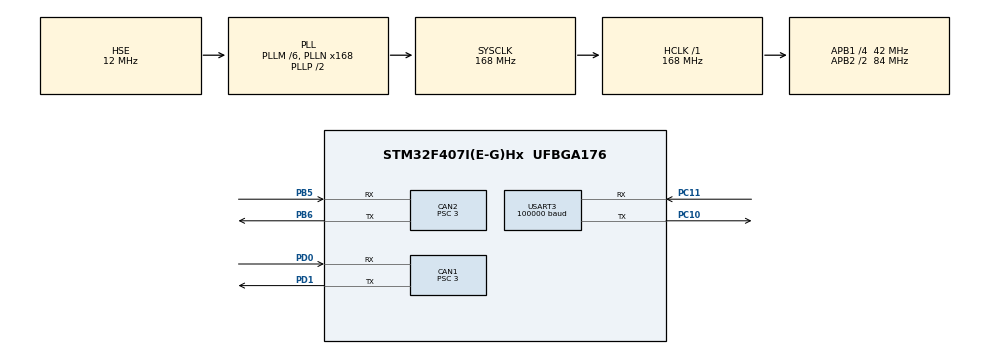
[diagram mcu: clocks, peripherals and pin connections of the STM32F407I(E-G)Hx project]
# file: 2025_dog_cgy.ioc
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CAN1.BS1=CAN_BS1_7TQ
CAN1.BS2=CAN_BS2_6TQ
CAN1.CalculateBaudRate=1000000
CAN1.CalculateTimeBit=1000
CAN1.CalculateTimeQuantum=71.42857142857143
CAN1.Prescaler=3
CAN2.BS1=CAN_BS1_10TQ
CAN2.BS2=CAN_BS2_3TQ
CAN2.CalculateBaudRate=1000000
CAN2.CalculateTimeBit=1000
CAN2.CalculateTimeQuantum=71.42857142857143
CAN2.Prescaler=3
Dma.Request0=USART3_RX
Dma.Request1=USART3_TX
Dma.USART3_RX.0.Direction=DMA_PERIPH_TO_MEMORY
Dma.USART3_RX.0.FIFOMode=DMA_FIFOMODE_DISABLE
Dma.USART3_RX.0.Instance=DMA1_Stream1
Dma.USART3_RX.0.MemDataAlignment=DMA_MDATAALIGN_BYTE
Dma.USART3_RX.0.MemInc=DMA_MINC_ENABLE
Dma.USART3_RX.0.Mode=DMA_CIRCULAR
Dma.USART3_RX.0.PeriphDataAlignment=DMA_PDATAALIGN_BYTE
Dma.USART3_RX.0.PeriphInc=DMA_PINC_DISABLE
Dma.USART3_RX.0.Priority=DMA_PRIORITY_LOW
Dma.USART3_TX.1.Direction=DMA_MEMORY_TO_PERIPH
Dma.USART3_TX.1.FIFOMode=DMA_FIFOMODE_DISABLE
Dma.USART3_TX.1.Instance=DMA1_Stream3
Dma.USART3_TX.1.MemDataAlignment=DMA_MDATAALIGN_BYTE
Dma.USART3_TX.1.MemInc=DMA_MINC_ENABLE
Dma.USART3_TX.1.Mode=DMA_CIRCULAR
Dma.USART3_TX.1.PeriphDataAlignment=DMA_PDATAALIGN_BYTE
Dma.USART3_TX.1.PeriphInc=DMA_PINC_DISABLE
Dma.USART3_TX.1.Priority=DMA_PRIORITY_LOW
FREERTOS.INCLUDE_vTaskDelayUntil=1
FREERTOS.Tasks01=WALK,0,128,walk_m,As weak,NULL,Dynamic,NULL,NULL;PostureControl,1,256,PostureControl_task,As weak,NULL,Dynamic,NULL,NULL;MOTOR_CTRL,0,128,MotorControl_task,As weak,NULL,Dynamic,NULL,NULL;Remote_control,2,128,RC_task,As weak,NULL,Dynamic,NULL,NULL
Mcu.Family=STM32F4
Mcu.Name=STM32F407I(E-G)Hx
Mcu.Package=UFBGA176
NVIC.CAN1_RX0_IRQn=true\:5\:0\:false\:false\:true\:true\:true\:true\:true
NVIC.CAN2_RX0_IRQn=true\:5\:0\:false\:false\:true\:true\:true\:true\:true
NVIC.DMA1_Stream1_IRQn=true\:5\:0\:false\:false\:true\:true\:false\:true\:true
NVIC.DMA1_Stream3_IRQn=true\:5\:0\:false\:false\:true\:true\:false\:true\:true
NVIC.PriorityGroup=NVIC_PRIORITYGROUP_4
NVIC.TIM7_IRQn=true\:15\:0\:false\:false\:true\:false\:true\:true\:true
NVIC.TimeBase=TIM7_IRQn
NVIC.TimeBaseIP=TIM7
NVIC.USART3_IRQn=true\:5\:0\:false\:false\:true\:true\:true\:true\:true
PA13.Mode=Serial_Wire
PA13.Signal=SYS_JTMS-SWDIO
PA14.Mode=Serial_Wire
PA14.Signal=SYS_JTCK-SWCLK
PB5.Mode=CAN_Activate
PB5.Signal=CAN2_RX
PB6.Mode=CAN_Activate
PB6.Signal=CAN2_TX
PC10.Mode=Asynchronous
PC10.Signal=USART3_TX
PC11.Mode=Asynchronous
PC11.Signal=USART3_RX
PD0.Mode=CAN_Activate
PD0.Signal=CAN1_RX
PD1.Mode=CAN_Activate
PD1.Signal=CAN1_TX
PH0-OSC_IN.Mode=HSE-External-Oscillator
PH0-OSC_IN.Signal=RCC_OSC_IN
PH1-OSC_OUT.Mode=HSE-External-Oscillator
PH1-OSC_OUT.Signal=RCC_OSC_OUT
ProjectManager.HeapSize=0x200
ProjectManager.StackSize=0x400
ProjectManager.TargetToolchain=MDK-ARM V5.32
RCC.48MHZClocksFreq_Value=84000000
RCC.AHBFreq_Value=168000000
RCC.APB1CLKDivider=RCC_HCLK_DIV4
RCC.APB1Freq_Value=42000000
RCC.APB1TimFreq_Value=84000000
RCC.APB2CLKDivider=RCC_HCLK_DIV2
RCC.APB2Freq_Value=84000000
RCC.APB2TimFreq_Value=168000000
RCC.CortexFreq_Value=168000000
RCC.HCLKFreq_Value=168000000
RCC.HSE_VALUE=12000000
RCC.HSI_VALUE=16000000
RCC.LSE_VALUE=32768
RCC.PLLM=6
RCC.PLLN=168
RCC.PLLSourceVirtual=RCC_PLLSOURCE_HSE
RCC.SYSCLKFreq_VALUE=168000000
RCC.SYSCLKSource=RCC_SYSCLKSOURCE_PLLCLK
RCC.VCOOutputFreq_Value=336000000
USART3.BaudRate=100000
USART3.VirtualMode=VM_ASYNC
VP_FREERTOS_VS_CMSIS_V1.Mode=CMSIS_V1
VP_SYS_VS_tim7.Mode=TIM7
board=custom

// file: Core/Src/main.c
/* USER CODE BEGIN Header */
/**
  ******************************************************************************
  * @file           : main.c
  * @brief          : Main program body
  ******************************************************************************
  * @attention
  *
  * Copyright (c) 2025 STMicroelectronics.
  * All rights reserved.
  *
  * This software is licensed under terms that can be found in the LICENSE file
  * in the root directory of this software component.
  * If no LICENSE file comes with this software, it is provided AS-IS.
  *
  ******************************************************************************
  */
/* USER CODE END Header */
#include "main.h"
#include "cmsis_os.h"
#include "can.h"
#include "dma.h"
#include "usart.h"
#include "gpio.h"

/* USER CODE BEGIN Includes */
#include "startup_main.h"
/* USER CODE END Includes */

void SystemClock_Config(void);
void MX_FREERTOS_Init(void);

int main(void)
{

  /* MCU Configuration--------------------------------------------------------*/

  /* Reset of all peripherals, Initializes the Flash interface and the Systick. */
  HAL_Init();

  /* Configure the system clock */
  SystemClock_Config();

  /* Initialize all configured peripherals */
  MX_GPIO_Init();
  MX_DMA_Init();
  MX_CAN1_Init();
  MX_CAN2_Init();
  MX_USART3_UART_Init();
  /* USER CODE BEGIN 2 */
	startup_main();
  /* USER CODE END 2 */

  /* Call init function for freertos objects (in cmsis_os2.c) */
  MX_FREERTOS_Init();

  /* Start scheduler */
  osKernelStart();

  /* We should never get here as control is now taken by the scheduler */

  /* Infinite loop */
  while (1)
  {

    /* USER CODE BEGIN 3 */
		HAL_Delay(5);
  }
  /* USER CODE END 3 */
}

void SystemClock_Config(void)
{
  RCC_OscInitTypeDef RCC_OscInitStruct = {0};
  RCC_ClkInitTypeDef RCC_ClkInitStruct = {0};

  /** Configure the main internal regulator output voltage
  */
  __HAL_RCC_PWR_CLK_ENABLE();
  __HAL_PWR_VOLTAGESCALING_CONFIG(PWR_REGULATOR_VOLTAGE_SCALE1);

  /** Initializes the RCC Oscillators according to the specified parameters
  * in the RCC_OscInitTypeDef structure.
  */
  RCC_OscInitStruct.OscillatorType = RCC_OSCILLATORTYPE_HSE;
  RCC_OscInitStruct.HSEState = RCC_HSE_ON;
  RCC_OscInitStruct.PLL.PLLState = RCC_PLL_ON;
  RCC_OscInitStruct.PLL.PLLSource = RCC_PLLSOURCE_HSE;
  RCC_OscInitStruct.PLL.PLLM = 6;
  RCC_OscInitStruct.PLL.PLLN = 168;
  RCC_OscInitStruct.PLL.PLLP = RCC_PLLP_DIV2;
  RCC_OscInitStruct.PLL.PLLQ = 4;
  if (HAL_RCC_OscConfig(&RCC_OscInitStruct) != HAL_OK)
  {
    Error_Handler();
  }

  /** Initializes the CPU, AHB and APB buses clocks
  */
  RCC_ClkInitStruct.ClockType = RCC_CLOCKTYPE_HCLK|RCC_CLOCKTYPE_SYSCLK
                              |RCC_CLOCKTYPE_PCLK1|RCC_CLOCKTYPE_PCLK2;
  RCC_ClkInitStruct.SYSCLKSource = RCC_SYSCLKSOURCE_PLLCLK;
  RCC_ClkInitStruct.AHBCLKDivider = RCC_SYSCLK_DIV1;
  RCC_ClkInitStruct.APB1CLKDivider = RCC_HCLK_DIV4;
  RCC_ClkInitStruct.APB2CLKDivider = RCC_HCLK_DIV2;

  if (HAL_RCC_ClockConfig(&RCC_ClkInitStruct, FLASH_LATENCY_5) != HAL_OK)
  {
    Error_Handler();
  }
}

void HAL_TIM_PeriodElapsedCallback(TIM_HandleTypeDef *htim)
{
  if (htim->Instance == TIM7) {
    HAL_IncTick();
  }
}

void Error_Handler(void)
{
  __disable_irq();
  while (1)
  {
  }
}

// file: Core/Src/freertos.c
/* USER CODE BEGIN Header */
/**
  ******************************************************************************
  * File Name          : freertos.c
  * Description        : Code for freertos applications
  ******************************************************************************
  * @attention
  *
  * Copyright (c) 2025 STMicroelectronics.
  * All rights reserved.
  *
  * This software is licensed under terms that can be found in the LICENSE file
  * in the root directory of this software component.
  * If no LICENSE file comes with this software, it is provided AS-IS.
  *
  ******************************************************************************
  */
/* USER CODE END Header */

#include "FreeRTOS.h"
#include "task.h"
#include "main.h"
#include "cmsis_os.h"

/* USER CODE BEGIN Includes */
//#include "task_user.h"

/* USER CODE END Includes */

osThreadId WALKHandle;
osThreadId PostureControlHandle;
osThreadId MOTOR_CTRLHandle;
osThreadId Remote_controlHandle;

void walk_m(void const * argument);
void PostureControl_task(void const * argument);
void MotorControl_task(void const * argument);
void RC_task(void const * argument);

void MX_FREERTOS_Init(void); /* (MISRA C 2004 rule 8.1) */

/* GetIdleTaskMemory prototype (linked to static allocation support) */
void vApplicationGetIdleTaskMemory( StaticTask_t **ppxIdleTaskTCBBuffer, StackType_t **ppxIdleTaskStackBuffer, uint32_t *pulIdleTaskStackSize );

/* USER CODE BEGIN GET_IDLE_TASK_MEMORY */
static StaticTask_t xIdleTaskTCBBuffer;
static StackType_t xIdleStack[configMINIMAL_STACK_SIZE];

void vApplicationGetIdleTaskMemory( StaticTask_t **ppxIdleTaskTCBBuffer, StackType_t **ppxIdleTaskStackBuffer, uint32_t *pulIdleTaskStackSize )
{
  *ppxIdleTaskTCBBuffer = &xIdleTaskTCBBuffer;
  *ppxIdleTaskStackBuffer = &xIdleStack[0];
  *pulIdleTaskStackSize = configMINIMAL_STACK_SIZE;
  /* place for user code */
}
/* USER CODE END GET_IDLE_TASK_MEMORY */

void MX_FREERTOS_Init(void) {

  /* Create the thread(s) */
  /* definition and creation of WALK */
//  osThreadDef(WALK, walk_m, osPriorityNormal, 0, 128);
//  WALKHandle = osThreadCreate(osThread(WALK), NULL);

  /* definition and creation of PostureControl */
  osThreadDef(PostureControl, PostureControl_task, osPriorityAboveNormal, 0, 256);
  PostureControlHandle = osThreadCreate(osThread(PostureControl), NULL);

  /* definition and creation of MOTOR_CTRL */
  osThreadDef(MOTOR_CTRL, MotorControl_task, osPriorityNormal, 0, 128);
  MOTOR_CTRLHandle = osThreadCreate(osThread(MOTOR_CTRL), NULL);

  /* definition and creation of Remote_control */
  osThreadDef(Remote_control, RC_task, osPriorityHigh, 0, 128);
  Remote_controlHandle = osThreadCreate(osThread(Remote_control), NULL);

}

__weak void walk_m(void const * argument)
{
  for(;;)
  {
    osDelay(1);
  }
}

__weak void PostureControl_task(void const * argument)
{
  for(;;)
  {
    osDelay(1);
  }
}

__weak void MotorControl_task(void const * argument)
{
  for(;;)
  {
    osDelay(1);
  }
}

__weak void RC_task(void const * argument)
{
  for(;;)
  {
    osDelay(1);
  }
}
